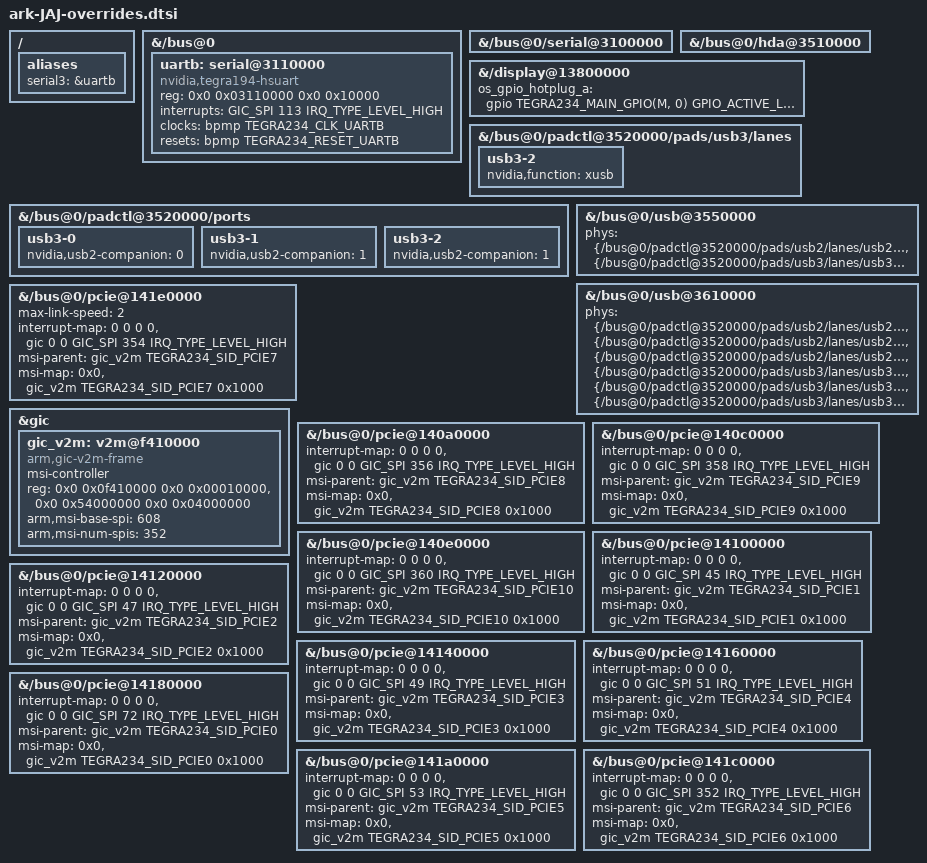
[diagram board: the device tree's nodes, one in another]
// SPDX-License-Identifier: GPL-2.0
/*
 * ARK JAJ carrier device-tree delta.
 *
 * build.sh appends an #include of this file to the stock
 * tegra234-p3768-0000+p3767-xxxx-nv-common.dtsi, so it is layered last over the
 * pristine BSP tree. Only ARK's delta lives here; everything else tracks the BSP.
 * Per-SKU model strings are stamped separately from products/JAJ/dtb_models.env.
 */

/* HDMI display: re-assigns display@13800000's nvidia,dcb-image with the HDMI blob. */
#include "tegra234-dcb-p3737-0000-p3701-0000-hdmi.dtsi"

/ {
	aliases {
		serial3 = &uartb;
	};
};

/* UARTB is wired on the carrier but undefined by the stock SoC dtsi. Declared as an
 * hsuart (not the tegra20-uart/8250 base) so it enumerates as /dev/ttyTHS*, like the
 * other Tegra UARTs. Stays PIO — stock's gpcdma RX-DMA corrupts the hsuart RX stream
 * at high baud (see UART-A below). */
&{/bus@0} {
	uartb: serial@3110000 {
		compatible = "nvidia,tegra194-hsuart";
		reg = <0x0 0x03110000 0x0 0x10000>;
		interrupts = <GIC_SPI 113 IRQ_TYPE_LEVEL_HIGH>;
		clocks = <&bpmp TEGRA234_CLK_UARTB>;
		resets = <&bpmp TEGRA234_RESET_UARTB>;
		reset-names = "serial";
		status = "okay";
	};
};

/* UART-A (ttyTHS1) inherits gpcdma RX/TX DMA from stock R36.5.0, and that DMA path
 * corrupts the hsuart RX stream at 3 Mbaud. Force PIO, like UART-B. */
&{/bus@0/serial@3100000} {
	/delete-property/ dmas;
	/delete-property/ dma-names;
};

/* HD-Audio is used on the carrier. */
&{/bus@0/hda@3510000} {
	status = "okay";
};

/* Hotplug detect line is active-low on the JAJ carrier. Also drop the stock
 * hdcp_enabled: it's inert on L4T (no HDCP) and triggers the JP6.2.2 DpAuxchCtrl DCE-RPC
 * regression on the DP->HDMI path. Native HDMI here shouldn't hit it, but keep HDCP off
 * across all carriers for consistency. */
&{/display@13800000} {
	os_gpio_hotplug_a = <&gpio TEGRA234_MAIN_GPIO(M, 0) GPIO_ACTIVE_LOW>;
	/delete-property/ hdcp_enabled;
};

/* Third USB3 lane for the dual USB-A port. */
&{/bus@0/padctl@3520000/pads/usb3/lanes} {
	usb3-2 {
		nvidia,function = "xusb";
		status = "okay";
	};
};

/* Carrier USB port mapping: usb3-0 = USB-C, usb3-1/usb3-2 = dual USB-A. */
&{/bus@0/padctl@3520000/ports} {
	usb3-0 { nvidia,usb2-companion = <0>; };
	usb3-1 { nvidia,usb2-companion = <1>; status = "okay"; };
	usb3-2 {
		nvidia,usb2-companion = <1>;
		status = "okay";
	};
};

&{/bus@0/usb@3550000} {
	phys = <&{/bus@0/padctl@3520000/pads/usb2/lanes/usb2-0}>,
	       <&{/bus@0/padctl@3520000/pads/usb3/lanes/usb3-0}>;
	phy-names = "usb2-0", "usb3-0";
};

&{/bus@0/usb@3610000} {
	phys = <&{/bus@0/padctl@3520000/pads/usb2/lanes/usb2-0}>,
	       <&{/bus@0/padctl@3520000/pads/usb2/lanes/usb2-1}>,
	       <&{/bus@0/padctl@3520000/pads/usb2/lanes/usb2-2}>,
	       <&{/bus@0/padctl@3520000/pads/usb3/lanes/usb3-0}>,
	       <&{/bus@0/padctl@3520000/pads/usb3/lanes/usb3-1}>,
	       <&{/bus@0/padctl@3520000/pads/usb3/lanes/usb3-2}>;
	phy-names = "usb2-0", "usb2-1", "usb2-2", "usb3-0",
		    "usb3-1", "usb3-2";
};

/* C7 is the 16-pin PCIe FFC header: one lane over unshielded flat flex, on a pinout
 * Raspberry Pi rates at 5 GT/s and treats 8 GT/s as best-effort. Left alone the link
 * trains at 8 GT/s with no margin and floods correctable AER.
 *
 * NVIDIA's SKU overlay pins every Orin Nano controller at Gen3 from UEFI, over the top
 * of this DTB, so build.sh drops its write for C7 to let the rate below reach the
 * kernel. See docs/device-tree.md. */
&{/bus@0/pcie@141e0000} {
	max-link-speed = <2>;
};

/* PCIe MSIs go to the GIC's v2m frame, as on JetPack 5, and not to each controller's DesignWare
 * MSI receiver. That receiver raises an MSI ahead of the device's earlier memory writes, so an NVMe
 * completion can be missed, and it sends every MSI to CPU 0. kernel_patches/0003 has the Tegra half:
 * the controller rewrites a write to the frame into the window at 0x54000000, which reaches the GIC
 * through the IOMMU. SPIs 608 to 959 are the range NVIDIA documents for PCIe MSIs.
 * The frame sits under the GIC, which needs address cells for it. Each PCIe interrupt map then
 * carries two parent address cells, so the stock maps are restated with them: UEFI's PCIe driver
 * asserts on a map that does not match the GIC's #address-cells. */
&gic {
	#address-cells = <2>;
	#size-cells = <2>;
	ranges;

	gic_v2m: v2m@f410000 {
		compatible = "arm,gic-v2m-frame";
		msi-controller;
		#msi-cells = <1>;
		reg = <0x0 0x0f410000 0x0 0x00010000>,	/* GICA */
		      <0x0 0x54000000 0x0 0x04000000>;	/* MSI window */
		reg-names = "gic_base", "msi_base";
		arm,msi-base-spi = <608>;
		arm,msi-num-spis = <352>;
	};
};

&{/bus@0/pcie@140a0000} {
	interrupt-map = <0 0 0 0 &gic 0 0 GIC_SPI 356 IRQ_TYPE_LEVEL_HIGH>;
	msi-parent = <&gic_v2m TEGRA234_SID_PCIE8>;
	msi-map = <0x0 &gic_v2m TEGRA234_SID_PCIE8 0x1000>;
};

&{/bus@0/pcie@140c0000} {
	interrupt-map = <0 0 0 0 &gic 0 0 GIC_SPI 358 IRQ_TYPE_LEVEL_HIGH>;
	msi-parent = <&gic_v2m TEGRA234_SID_PCIE9>;
	msi-map = <0x0 &gic_v2m TEGRA234_SID_PCIE9 0x1000>;
};

&{/bus@0/pcie@140e0000} {
	interrupt-map = <0 0 0 0 &gic 0 0 GIC_SPI 360 IRQ_TYPE_LEVEL_HIGH>;
	msi-parent = <&gic_v2m TEGRA234_SID_PCIE10>;
	msi-map = <0x0 &gic_v2m TEGRA234_SID_PCIE10 0x1000>;
};

&{/bus@0/pcie@14100000} {
	interrupt-map = <0 0 0 0 &gic 0 0 GIC_SPI 45 IRQ_TYPE_LEVEL_HIGH>;
	msi-parent = <&gic_v2m TEGRA234_SID_PCIE1>;
	msi-map = <0x0 &gic_v2m TEGRA234_SID_PCIE1 0x1000>;
};

&{/bus@0/pcie@14120000} {
	interrupt-map = <0 0 0 0 &gic 0 0 GIC_SPI 47 IRQ_TYPE_LEVEL_HIGH>;
	msi-parent = <&gic_v2m TEGRA234_SID_PCIE2>;
	msi-map = <0x0 &gic_v2m TEGRA234_SID_PCIE2 0x1000>;
};

&{/bus@0/pcie@14140000} {
	interrupt-map = <0 0 0 0 &gic 0 0 GIC_SPI 49 IRQ_TYPE_LEVEL_HIGH>;
	msi-parent = <&gic_v2m TEGRA234_SID_PCIE3>;
	msi-map = <0x0 &gic_v2m TEGRA234_SID_PCIE3 0x1000>;
};

&{/bus@0/pcie@14160000} {
	interrupt-map = <0 0 0 0 &gic 0 0 GIC_SPI 51 IRQ_TYPE_LEVEL_HIGH>;
	msi-parent = <&gic_v2m TEGRA234_SID_PCIE4>;
	msi-map = <0x0 &gic_v2m TEGRA234_SID_PCIE4 0x1000>;
};

&{/bus@0/pcie@14180000} {
	interrupt-map = <0 0 0 0 &gic 0 0 GIC_SPI 72 IRQ_TYPE_LEVEL_HIGH>;
	msi-parent = <&gic_v2m TEGRA234_SID_PCIE0>;
	msi-map = <0x0 &gic_v2m TEGRA234_SID_PCIE0 0x1000>;
};

&{/bus@0/pcie@141a0000} {
	interrupt-map = <0 0 0 0 &gic 0 0 GIC_SPI 53 IRQ_TYPE_LEVEL_HIGH>;
	msi-parent = <&gic_v2m TEGRA234_SID_PCIE5>;
	msi-map = <0x0 &gic_v2m TEGRA234_SID_PCIE5 0x1000>;
};

&{/bus@0/pcie@141c0000} {
	interrupt-map = <0 0 0 0 &gic 0 0 GIC_SPI 352 IRQ_TYPE_LEVEL_HIGH>;
	msi-parent = <&gic_v2m TEGRA234_SID_PCIE6>;
	msi-map = <0x0 &gic_v2m TEGRA234_SID_PCIE6 0x1000>;
};

&{/bus@0/pcie@141e0000} {
	interrupt-map = <0 0 0 0 &gic 0 0 GIC_SPI 354 IRQ_TYPE_LEVEL_HIGH>;
	msi-parent = <&gic_v2m TEGRA234_SID_PCIE7>;
	msi-map = <0x0 &gic_v2m TEGRA234_SID_PCIE7 0x1000>;
};
